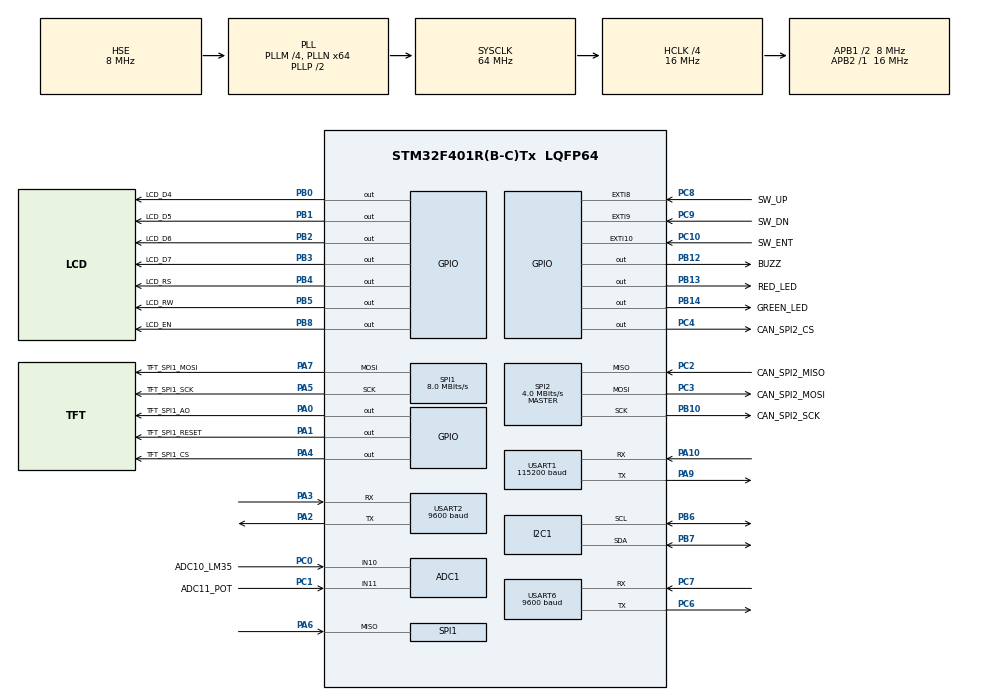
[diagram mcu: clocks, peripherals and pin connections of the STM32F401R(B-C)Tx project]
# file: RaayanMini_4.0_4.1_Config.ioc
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ADC1.Channel-0\#ChannelRegularConversion=ADC_CHANNEL_10
ADC1.NbrOfConversionFlag=1
ADC1.Rank-0\#ChannelRegularConversion=1
ADC1.SamplingTime-0\#ChannelRegularConversion=ADC_SAMPLETIME_3CYCLES
ADC1.master=1
Mcu.Family=STM32F4
Mcu.Name=STM32F401R(B-C)Tx
Mcu.Package=LQFP64
NVIC.EXTI15_10_IRQn=true\:0\:0\:false\:false\:true\:true\:true\:true
NVIC.EXTI9_5_IRQn=true\:0\:0\:false\:false\:true\:true\:true\:true
NVIC.PriorityGroup=NVIC_PRIORITYGROUP_4
NVIC.RCC_IRQn=true\:0\:0\:false\:false\:true\:true\:false\:true
NVIC.SPI1_IRQn=true\:0\:0\:false\:false\:true\:true\:true\:true
NVIC.SPI2_IRQn=true\:0\:0\:false\:false\:true\:true\:true\:true
NVIC.USART1_IRQn=true\:0\:0\:false\:false\:true\:true\:true\:true
NVIC.USART2_IRQn=true\:0\:0\:false\:false\:true\:true\:true\:true
PA0-WKUP.GPIO_Label=TFT_SPI1_AO
PA0-WKUP.Signal=GPIO_Output
PA1.GPIO_Label=TFT_SPI1_RESET
PA1.Signal=GPIO_Output
PA10.Mode=Asynchronous
PA10.Signal=USART1_RX
PA13.Mode=Serial_Wire
PA13.Signal=SYS_JTMS-SWDIO
PA14.Mode=Serial_Wire
PA14.Signal=SYS_JTCK-SWCLK
PA2.Mode=Asynchronous
PA2.Signal=USART2_TX
PA3.Mode=Asynchronous
PA3.Signal=USART2_RX
PA4.GPIO_Label=TFT_SPI1_CS
PA4.Signal=GPIO_Output
PA5.GPIO_Label=TFT_SPI1_SCK
PA5.Mode=Full_Duplex_Master
PA5.Signal=SPI1_SCK
PA6.Mode=Full_Duplex_Master
PA6.Signal=SPI1_MISO
PA7.GPIO_Label=TFT_SPI1_MOSI
PA7.Mode=Full_Duplex_Master
PA7.Signal=SPI1_MOSI
PA9.Mode=Asynchronous
PA9.Signal=USART1_TX
PB0.GPIO_Label=LCD_D4
PB0.GPIO_ModeDefaultOutputPP=GPIO_MODE_OUTPUT_PP
PB0.GPIO_PuPd=GPIO_NOPULL
PB0.GPIO_Speed=GPIO_SPEED_FREQ_LOW
PB0.PinState=GPIO_PIN_RESET
PB0.Signal=GPIO_Output
PB1.GPIO_Label=LCD_D5
PB1.GPIO_ModeDefaultOutputPP=GPIO_MODE_OUTPUT_PP
PB1.GPIO_PuPd=GPIO_NOPULL
PB1.GPIO_Speed=GPIO_SPEED_FREQ_LOW
PB1.PinState=GPIO_PIN_RESET
PB1.Signal=GPIO_Output
PB10.GPIO_Label=CAN_SPI2_SCK
PB10.Mode=Full_Duplex_Master
PB10.Signal=SPI2_SCK
PB12.GPIO_Label=BUZZ
PB12.Signal=GPIO_Output
PB13.GPIO_Label=RED_LED
PB13.Signal=GPIO_Output
PB14.GPIO_Label=GREEN_LED
PB14.Signal=GPIO_Output
PB2.GPIO_Label=LCD_D6
PB2.GPIO_ModeDefaultOutputPP=GPIO_MODE_OUTPUT_PP
PB2.GPIO_PuPd=GPIO_NOPULL
PB2.GPIO_Speed=GPIO_SPEED_FREQ_LOW
PB2.PinState=GPIO_PIN_RESET
PB2.Signal=GPIO_Output
PB3.GPIO_Label=LCD_D7
PB3.GPIO_ModeDefaultOutputPP=GPIO_MODE_OUTPUT_PP
PB3.GPIO_PuPd=GPIO_NOPULL
PB3.GPIO_Speed=GPIO_SPEED_FREQ_LOW
PB3.PinState=GPIO_PIN_RESET
PB3.Signal=GPIO_Output
PB4.GPIO_Label=LCD_RS
PB4.GPIO_ModeDefaultOutputPP=GPIO_MODE_OUTPUT_PP
PB4.GPIO_PuPd=GPIO_NOPULL
PB4.GPIO_Speed=GPIO_SPEED_FREQ_LOW
PB4.PinState=GPIO_PIN_RESET
PB4.Signal=GPIO_Output
PB5.GPIO_Label=LCD_RW
PB5.GPIO_ModeDefaultOutputPP=GPIO_MODE_OUTPUT_PP
PB5.GPIO_PuPd=GPIO_NOPULL
PB5.GPIO_Speed=GPIO_SPEED_FREQ_LOW
PB5.PinState=GPIO_PIN_RESET
PB5.Signal=GPIO_Output
PB6.GPIO_Pu=GPIO_PULLUP
PB6.Mode=I2C
PB6.Signal=I2C1_SCL
PB7.GPIO_Pu=GPIO_PULLUP
PB7.Mode=I2C
PB7.Signal=I2C1_SDA
PB8.GPIO_Label=LCD_EN
PB8.GPIO_ModeDefaultOutputPP=GPIO_MODE_OUTPUT_PP
PB8.GPIO_PuPd=GPIO_NOPULL
PB8.GPIO_Speed=GPIO_SPEED_FREQ_LOW
PB8.PinState=GPIO_PIN_RESET
PB8.Signal=GPIO_Output
PC0.GPIO_Label=ADC10_LM35
PC0.Signal=ADCx_IN10
PC1.GPIO_Label=ADC11_POT
PC1.Signal=ADCx_IN11
PC10.GPIO_Label=SW_ENT
PC10.GPIO_PuPd=GPIO_PULLUP
PC10.Signal=GPXTI10
PC14-OSC32_IN.Mode=LSE-External-Oscillator
PC14-OSC32_IN.Signal=RCC_OSC32_IN
PC15-OSC32_OUT.Mode=LSE-External-Oscillator
PC15-OSC32_OUT.Signal=RCC_OSC32_OUT
PC2.GPIO_Label=CAN_SPI2_MISO
PC2.Mode=Full_Duplex_Master
PC2.Signal=SPI2_MISO
PC3.GPIO_Label=CAN_SPI2_MOSI
PC3.Mode=Full_Duplex_Master
PC3.Signal=SPI2_MOSI
PC4.GPIO_Label=CAN_SPI2_CS
PC4.Signal=GPIO_Output
PC6.Mode=Asynchronous
PC6.Signal=USART6_TX
PC7.Mode=Asynchronous
PC7.Signal=USART6_RX
PC8.GPIO_Label=SW_UP
PC8.GPIO_ModeDefaultEXTI=GPIO_MODE_IT_FALLING
PC8.GPIO_PuPd=GPIO_PULLUP
PC8.Signal=GPXTI8
PC9.GPIO_Label=SW_DN
PC9.GPIO_ModeDefaultEXTI=GPIO_MODE_IT_FALLING
PC9.GPIO_PuPd=GPIO_PULLUP
PC9.Signal=GPXTI9
PH0\ -\ OSC_IN.Mode=HSE-External-Oscillator
PH0\ -\ OSC_IN.Signal=RCC_OSC_IN
PH1\ -\ OSC_OUT.Mode=HSE-External-Oscillator
PH1\ -\ OSC_OUT.Signal=RCC_OSC_OUT
ProjectManager.HeapSize=0x200
ProjectManager.StackSize=0x400
ProjectManager.TargetToolchain=MDK-ARM V5
RCC.48MHZClocksFreq_Value=18285714.285714287
RCC.AHBCLKDivider=RCC_SYSCLK_DIV4
RCC.AHBFreq_Value=16000000
RCC.APB1CLKDivider=RCC_HCLK_DIV2
RCC.APB1Freq_Value=8000000
RCC.APB1TimFreq_Value=16000000
RCC.APB2Freq_Value=16000000
RCC.APB2TimFreq_Value=16000000
RCC.CortexFreq_Value=16000000
RCC.HCLKFreq_Value=16000000
RCC.HSE_VALUE=8000000
RCC.HSI_VALUE=16000000
RCC.PLLM=4
RCC.PLLN=64
RCC.PLLQ=7
RCC.PLLSourceVirtual=RCC_PLLSOURCE_HSE
RCC.RCC_RTC_Clock_Source=RCC_RTCCLKSOURCE_LSI
RCC.RCC_RTC_Clock_SourceVirtual=RCC_RTCCLKSOURCE_LSE
RCC.SYSCLKFreq_VALUE=64000000
RCC.SYSCLKSource=RCC_SYSCLKSOURCE_PLLCLK
RCC.VCOOutputFreq_Value=128000000
SH.ADCx_IN10.0=ADC1_IN10,IN10
SH.ADCx_IN11.0=ADC1_IN11,IN11
SPI1.BaudRatePrescaler=SPI_BAUDRATEPRESCALER_2
SPI1.CalculateBaudRate=8.0 MBits/s
SPI1.Direction=SPI_DIRECTION_2LINES
SPI1.Mode=SPI_MODE_MASTER
SPI1.VirtualType=VM_MASTER
SPI2.BaudRatePrescaler=SPI_BAUDRATEPRESCALER_2
SPI2.CalculateBaudRate=4.0 MBits/s
SPI2.Direction=SPI_DIRECTION_2LINES
SPI2.Mode=SPI_MODE_MASTER
SPI2.VirtualType=VM_MASTER
USART1.BaudRate=115200
USART1.VirtualMode=VM_ASYNC
USART2.BaudRate=9600
USART2.VirtualMode=VM_ASYNC
USART6.BaudRate=9600
USART6.VirtualMode=VM_ASYNC
VP_RTC_VS_RTC_Activate.Mode=RTC_Enabled
board=custom

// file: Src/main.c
/* USER CODE BEGIN Header */
/**
  ******************************************************************************
  * @file           : main.c
  * @brief          : Main program body
  ******************************************************************************
  * @attention
  *
  * Copyright (c) 2023 STMicroelectronics.
  * All rights reserved.
  *
  * This software is licensed under terms that can be found in the LICENSE file
  * in the root directory of this software component.
  * If no LICENSE file comes with this software, it is provided AS-IS.
  *
  ******************************************************************************
  */
/* USER CODE END Header */
#include "main.h"

/* USER CODE BEGIN Includes */
#include <string.h>
#include <lcd.h>
/* USER CODE END Includes */

 ADC_HandleTypeDef hadc1;

I2C_HandleTypeDef hi2c1;

RTC_HandleTypeDef hrtc;

SPI_HandleTypeDef hspi1;
SPI_HandleTypeDef hspi2;

UART_HandleTypeDef huart1;
UART_HandleTypeDef huart2;
UART_HandleTypeDef huart6;

void SystemClock_Config(void);
static void MX_GPIO_Init(void);
static void MX_ADC1_Init(void);
static void MX_I2C1_Init(void);
static void MX_SPI1_Init(void);
static void MX_USART1_UART_Init(void);
static void MX_USART2_UART_Init(void);
static void MX_USART6_UART_Init(void);
static void MX_RTC_Init(void);
static void MX_SPI2_Init(void);

/* USER CODE BEGIN 0 */
unsigned char RX_Buff[10];
char Lcd_Buff[30];
int 		ISR_Flag=0;
/* USER CODE END 0 */

int main(void)
{

  /* MCU Configuration--------------------------------------------------------*/

  /* Reset of all peripherals, Initializes the Flash interface and the Systick. */
  HAL_Init();

  /* USER CODE BEGIN Init */
	char Rx_Buff,Tx_Buff='A';

  /* USER CODE END Init */

  /* Configure the system clock */
  SystemClock_Config();

  /* Initialize all configured peripherals */
  MX_GPIO_Init();
  MX_ADC1_Init();
  MX_I2C1_Init();
  MX_SPI1_Init();
  MX_USART1_UART_Init();
  MX_USART2_UART_Init();
  MX_USART6_UART_Init();
  MX_RTC_Init();
  MX_SPI2_Init();
  /* USER CODE BEGIN 2 */
	RM_LCD_Init();
	RM_LCD_Clear();
	HAL_Delay(100);
	RM_LCD_Write_Str(3,0,"SPI LoopBack");
	HAL_Delay(3000);
  /* USER CODE END 2 */

  /* Infinite loop */
  while (1)
  {

    /* USER CODE BEGIN 3 */
		 HAL_SPI_TransmitReceive_IT(&hspi1,(uint8_t *)&Tx_Buff, (uint8_t *)&Rx_Buff,1);
		 RM_LCD_Write_CMD(0xC0);
     RM_LCD_Write_DATA(Rx_Buff);
  }
  /* USER CODE END 3 */
}

void SystemClock_Config(void)
{
  RCC_OscInitTypeDef RCC_OscInitStruct = {0};
  RCC_ClkInitTypeDef RCC_ClkInitStruct = {0};

  /** Configure the main internal regulator output voltage
  */
  __HAL_RCC_PWR_CLK_ENABLE();
  __HAL_PWR_VOLTAGESCALING_CONFIG(PWR_REGULATOR_VOLTAGE_SCALE2);

  /** Initializes the RCC Oscillators according to the specified parameters
  * in the RCC_OscInitTypeDef structure.
  */
  RCC_OscInitStruct.OscillatorType = RCC_OSCILLATORTYPE_LSI|RCC_OSCILLATORTYPE_HSE;
  RCC_OscInitStruct.HSEState = RCC_HSE_ON;
  RCC_OscInitStruct.LSIState = RCC_LSI_ON;
  RCC_OscInitStruct.PLL.PLLState = RCC_PLL_ON;
  RCC_OscInitStruct.PLL.PLLSource = RCC_PLLSOURCE_HSE;
  RCC_OscInitStruct.PLL.PLLM = 4;
  RCC_OscInitStruct.PLL.PLLN = 64;
  RCC_OscInitStruct.PLL.PLLP = RCC_PLLP_DIV2;
  RCC_OscInitStruct.PLL.PLLQ = 7;
  if (HAL_RCC_OscConfig(&RCC_OscInitStruct) != HAL_OK)
  {
    Error_Handler();
  }

  /** Initializes the CPU, AHB and APB buses clocks
  */
  RCC_ClkInitStruct.ClockType = RCC_CLOCKTYPE_HCLK|RCC_CLOCKTYPE_SYSCLK
                              |RCC_CLOCKTYPE_PCLK1|RCC_CLOCKTYPE_PCLK2;
  RCC_ClkInitStruct.SYSCLKSource = RCC_SYSCLKSOURCE_PLLCLK;
  RCC_ClkInitStruct.AHBCLKDivider = RCC_SYSCLK_DIV4;
  RCC_ClkInitStruct.APB1CLKDivider = RCC_HCLK_DIV2;
  RCC_ClkInitStruct.APB2CLKDivider = RCC_HCLK_DIV1;

  if (HAL_RCC_ClockConfig(&RCC_ClkInitStruct, FLASH_LATENCY_0) != HAL_OK)
  {
    Error_Handler();
  }
}

static void MX_ADC1_Init(void)
{

  ADC_ChannelConfTypeDef sConfig = {0};

  /** Configure the global features of the ADC (Clock, Resolution, Data Alignment and number of conversion)
  */
  hadc1.Instance = ADC1;
  hadc1.Init.ClockPrescaler = ADC_CLOCK_SYNC_PCLK_DIV2;
  hadc1.Init.Resolution = ADC_RESOLUTION_12B;
  hadc1.Init.ScanConvMode = DISABLE;
  hadc1.Init.ContinuousConvMode = DISABLE;
  hadc1.Init.DiscontinuousConvMode = DISABLE;
  hadc1.Init.ExternalTrigConvEdge = ADC_EXTERNALTRIGCONVEDGE_NONE;
  hadc1.Init.ExternalTrigConv = ADC_SOFTWARE_START;
  hadc1.Init.DataAlign = ADC_DATAALIGN_RIGHT;
  hadc1.Init.NbrOfConversion = 1;
  hadc1.Init.DMAContinuousRequests = DISABLE;
  hadc1.Init.EOCSelection = ADC_EOC_SINGLE_CONV;
  if (HAL_ADC_Init(&hadc1) != HAL_OK)
  {
    Error_Handler();
  }

  /** Configure for the selected ADC regular channel its corresponding rank in the sequencer and its sample time.
  */
  sConfig.Channel = ADC_CHANNEL_10;
  sConfig.Rank = 1;
  sConfig.SamplingTime = ADC_SAMPLETIME_3CYCLES;
  if (HAL_ADC_ConfigChannel(&hadc1, &sConfig) != HAL_OK)
  {
    Error_Handler();
  }

}

static void MX_I2C1_Init(void)
{

  hi2c1.Instance = I2C1;
  hi2c1.Init.ClockSpeed = 100000;
  hi2c1.Init.DutyCycle = I2C_DUTYCYCLE_2;
  hi2c1.Init.OwnAddress1 = 0;
  hi2c1.Init.AddressingMode = I2C_ADDRESSINGMODE_7BIT;
  hi2c1.Init.DualAddressMode = I2C_DUALADDRESS_DISABLE;
  hi2c1.Init.OwnAddress2 = 0;
  hi2c1.Init.GeneralCallMode = I2C_GENERALCALL_DISABLE;
  hi2c1.Init.NoStretchMode = I2C_NOSTRETCH_DISABLE;
  if (HAL_I2C_Init(&hi2c1) != HAL_OK)
  {
    Error_Handler();
  }

}

static void MX_RTC_Init(void)
{

  /** Initialize RTC Only
  */
  hrtc.Instance = RTC;
  hrtc.Init.HourFormat = RTC_HOURFORMAT_24;
  hrtc.Init.AsynchPrediv = 127;
  hrtc.Init.SynchPrediv = 255;
  hrtc.Init.OutPut = RTC_OUTPUT_DISABLE;
  hrtc.Init.OutPutPolarity = RTC_OUTPUT_POLARITY_HIGH;
  hrtc.Init.OutPutType = RTC_OUTPUT_TYPE_OPENDRAIN;
  if (HAL_RTC_Init(&hrtc) != HAL_OK)
  {
    Error_Handler();
  }

}

static void MX_SPI1_Init(void)
{

  /* SPI1 parameter configuration*/
  hspi1.Instance = SPI1;
  hspi1.Init.Mode = SPI_MODE_MASTER;
  hspi1.Init.Direction = SPI_DIRECTION_2LINES;
  hspi1.Init.DataSize = SPI_DATASIZE_8BIT;
  hspi1.Init.CLKPolarity = SPI_POLARITY_LOW;
  hspi1.Init.CLKPhase = SPI_PHASE_1EDGE;
  hspi1.Init.NSS = SPI_NSS_SOFT;
  hspi1.Init.BaudRatePrescaler = SPI_BAUDRATEPRESCALER_2;
  hspi1.Init.FirstBit = SPI_FIRSTBIT_MSB;
  hspi1.Init.TIMode = SPI_TIMODE_DISABLE;
  hspi1.Init.CRCCalculation = SPI_CRCCALCULATION_DISABLE;
  hspi1.Init.CRCPolynomial = 10;
  if (HAL_SPI_Init(&hspi1) != HAL_OK)
  {
    Error_Handler();
  }

}

static void MX_SPI2_Init(void)
{

  /* SPI2 parameter configuration*/
  hspi2.Instance = SPI2;
  hspi2.Init.Mode = SPI_MODE_MASTER;
  hspi2.Init.Direction = SPI_DIRECTION_2LINES;
  hspi2.Init.DataSize = SPI_DATASIZE_8BIT;
  hspi2.Init.CLKPolarity = SPI_POLARITY_LOW;
  hspi2.Init.CLKPhase = SPI_PHASE_1EDGE;
  hspi2.Init.NSS = SPI_NSS_SOFT;
  hspi2.Init.BaudRatePrescaler = SPI_BAUDRATEPRESCALER_2;
  hspi2.Init.FirstBit = SPI_FIRSTBIT_MSB;
  hspi2.Init.TIMode = SPI_TIMODE_DISABLE;
  hspi2.Init.CRCCalculation = SPI_CRCCALCULATION_DISABLE;
  hspi2.Init.CRCPolynomial = 10;
  if (HAL_SPI_Init(&hspi2) != HAL_OK)
  {
    Error_Handler();
  }

}

static void MX_USART1_UART_Init(void)
{

  huart1.Instance = USART1;
  huart1.Init.BaudRate = 115200;
  huart1.Init.WordLength = UART_WORDLENGTH_8B;
  huart1.Init.StopBits = UART_STOPBITS_1;
  huart1.Init.Parity = UART_PARITY_NONE;
  huart1.Init.Mode = UART_MODE_TX_RX;
  huart1.Init.HwFlowCtl = UART_HWCONTROL_NONE;
  huart1.Init.OverSampling = UART_OVERSAMPLING_16;
  if (HAL_UART_Init(&huart1) != HAL_OK)
  {
    Error_Handler();
  }

}

static void MX_USART2_UART_Init(void)
{

  huart2.Instance = USART2;
  huart2.Init.BaudRate = 9600;
  huart2.Init.WordLength = UART_WORDLENGTH_8B;
  huart2.Init.StopBits = UART_STOPBITS_1;
  huart2.Init.Parity = UART_PARITY_NONE;
  huart2.Init.Mode = UART_MODE_TX_RX;
  huart2.Init.HwFlowCtl = UART_HWCONTROL_NONE;
  huart2.Init.OverSampling = UART_OVERSAMPLING_16;
  if (HAL_UART_Init(&huart2) != HAL_OK)
  {
    Error_Handler();
  }

}

static void MX_USART6_UART_Init(void)
{

  huart6.Instance = USART6;
  huart6.Init.BaudRate = 9600;
  huart6.Init.WordLength = UART_WORDLENGTH_8B;
  huart6.Init.StopBits = UART_STOPBITS_1;
  huart6.Init.Parity = UART_PARITY_NONE;
  huart6.Init.Mode = UART_MODE_TX_RX;
  huart6.Init.HwFlowCtl = UART_HWCONTROL_NONE;
  huart6.Init.OverSampling = UART_OVERSAMPLING_16;
  if (HAL_UART_Init(&huart6) != HAL_OK)
  {
    Error_Handler();
  }

}

static void MX_GPIO_Init(void)
{
  GPIO_InitTypeDef GPIO_InitStruct = {0};

  /* GPIO Ports Clock Enable */
  __HAL_RCC_GPIOC_CLK_ENABLE();
  __HAL_RCC_GPIOH_CLK_ENABLE();
  __HAL_RCC_GPIOA_CLK_ENABLE();
  __HAL_RCC_GPIOB_CLK_ENABLE();

  /*Configure GPIO pin Output Level */
  HAL_GPIO_WritePin(GPIOA, TFT_SPI1_AO_Pin|TFT_SPI1_RESET_Pin|TFT_SPI1_CS_Pin, GPIO_PIN_RESET);

  /*Configure GPIO pin Output Level */
  HAL_GPIO_WritePin(CAN_SPI2_CS_GPIO_Port, CAN_SPI2_CS_Pin, GPIO_PIN_RESET);

  /*Configure GPIO pin Output Level */
  HAL_GPIO_WritePin(GPIOB, LCD_D4_Pin|LCD_D5_Pin|LCD_D6_Pin|BUZZ_Pin
                          |RED_LED_Pin|GREEN_LED_Pin|LCD_D7_Pin|LCD_RS_Pin
                          |LCD_RW_Pin|LCD_EN_Pin, GPIO_PIN_RESET);

  /*Configure GPIO pins : TFT_SPI1_AO_Pin TFT_SPI1_RESET_Pin TFT_SPI1_CS_Pin */
  GPIO_InitStruct.Pin = TFT_SPI1_AO_Pin|TFT_SPI1_RESET_Pin|TFT_SPI1_CS_Pin;
  GPIO_InitStruct.Mode = GPIO_MODE_OUTPUT_PP;
  GPIO_InitStruct.Pull = GPIO_NOPULL;
  GPIO_InitStruct.Speed = GPIO_SPEED_FREQ_LOW;
  HAL_GPIO_Init(GPIOA, &GPIO_InitStruct);

  /*Configure GPIO pin : CAN_SPI2_CS_Pin */
  GPIO_InitStruct.Pin = CAN_SPI2_CS_Pin;
  GPIO_InitStruct.Mode = GPIO_MODE_OUTPUT_PP;
  GPIO_InitStruct.Pull = GPIO_NOPULL;
  GPIO_InitStruct.Speed = GPIO_SPEED_FREQ_LOW;
  HAL_GPIO_Init(CAN_SPI2_CS_GPIO_Port, &GPIO_InitStruct);

  /*Configure GPIO pins : LCD_D4_Pin LCD_D5_Pin LCD_D6_Pin BUZZ_Pin
                           RED_LED_Pin GREEN_LED_Pin LCD_D7_Pin LCD_RS_Pin
                           LCD_RW_Pin LCD_EN_Pin */
  GPIO_InitStruct.Pin = LCD_D4_Pin|LCD_D5_Pin|LCD_D6_Pin|BUZZ_Pin
                          |RED_LED_Pin|GREEN_LED_Pin|LCD_D7_Pin|LCD_RS_Pin
                          |LCD_RW_Pin|LCD_EN_Pin;
  GPIO_InitStruct.Mode = GPIO_MODE_OUTPUT_PP;
  GPIO_InitStruct.Pull = GPIO_NOPULL;
  GPIO_InitStruct.Speed = GPIO_SPEED_FREQ_LOW;
  HAL_GPIO_Init(GPIOB, &GPIO_InitStruct);

  /*Configure GPIO pins : SW_UP_Pin SW_DN_Pin */
  GPIO_InitStruct.Pin = SW_UP_Pin|SW_DN_Pin;
  GPIO_InitStruct.Mode = GPIO_MODE_IT_FALLING;
  GPIO_InitStruct.Pull = GPIO_PULLUP;
  HAL_GPIO_Init(GPIOC, &GPIO_InitStruct);

  /*Configure GPIO pin : SW_ENT_Pin */
  GPIO_InitStruct.Pin = SW_ENT_Pin;
  GPIO_InitStruct.Mode = GPIO_MODE_IT_RISING;
  GPIO_InitStruct.Pull = GPIO_PULLUP;
  HAL_GPIO_Init(SW_ENT_GPIO_Port, &GPIO_InitStruct);

  /* EXTI interrupt init*/
  HAL_NVIC_SetPriority(EXTI9_5_IRQn, 0, 0);
  HAL_NVIC_EnableIRQ(EXTI9_5_IRQn);

  HAL_NVIC_SetPriority(EXTI15_10_IRQn, 0, 0);
  HAL_NVIC_EnableIRQ(EXTI15_10_IRQn);

}

void Error_Handler(void)
{
  __disable_irq();
  while (1)
  {
  }
}
